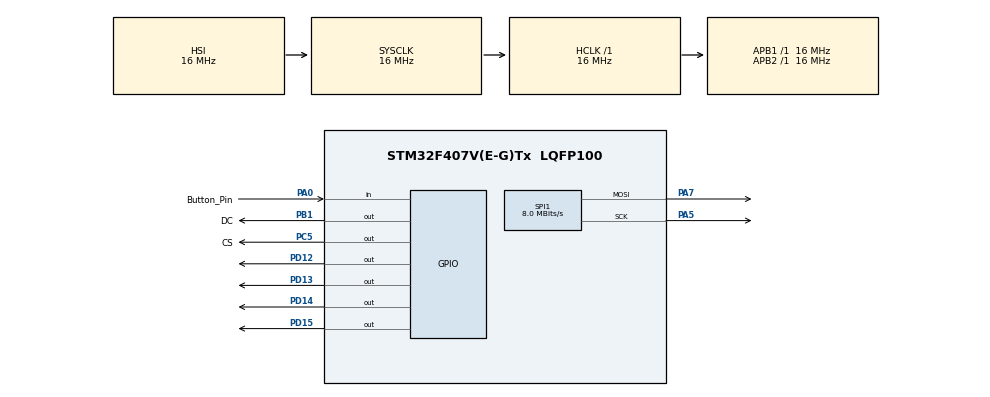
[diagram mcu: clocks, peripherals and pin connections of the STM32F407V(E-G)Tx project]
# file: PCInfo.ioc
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Mcu.Family=STM32F4
Mcu.Name=STM32F407V(E-G)Tx
Mcu.Package=LQFP100
NVIC.PriorityGroup=NVIC_PRIORITYGROUP_4
PA0-WKUP.GPIO_Label=Button_Pin
PA0-WKUP.Signal=GPIO_Input
PA13.Mode=Serial_Wire
PA13.Signal=SYS_JTMS-SWDIO
PA14.Mode=Serial_Wire
PA14.Signal=SYS_JTCK-SWCLK
PA5.Mode=TX_Only_Simplex_Unidirect_Master
PA5.Signal=SPI1_SCK
PA7.Mode=TX_Only_Simplex_Unidirect_Master
PA7.Signal=SPI1_MOSI
PB1.GPIO_Label=DC
PB1.Signal=GPIO_Output
PC5.GPIO_Label=CS
PC5.Signal=GPIO_Output
PD12.Signal=GPIO_Output
PD13.Signal=GPIO_Output
PD14.Signal=GPIO_Output
PD15.Signal=GPIO_Output
ProjectManager.HeapSize=0x200
ProjectManager.StackSize=0x400
ProjectManager.TargetToolchain=SW4STM32
RCC.AHBFreq_Value=16000000
RCC.APB1Freq_Value=16000000
RCC.APB2Freq_Value=16000000
RCC.ClockTypeHCLK=RCC_CLOCKTYPE_HCLK
RCC.ClockTypePCLK1=RCC_CLOCKTYPE_PCLK1
RCC.ClockTypePCLK2=RCC_CLOCKTYPE_PCLK2
RCC.ClockTypeSysClk=RCC_CLOCKTYPE_SYSCLK
RCC.CortexFreq_Value=16000000
RCC.EnableExtClockForI2S=false
RCC.EnableHSE=false
RCC.EnableHSERTCDevisor=false
RCC.EnableLSE=false
RCC.EnableLSERTC=false
RCC.ExtClockEnable=false
RCC.HSEState=RCC_HSE_OFF
RCC.HSE_VALUE=25000000
RCC.HSIState=RCC_HSI_ON
RCC.HSI_VALUE=16000000
RCC.I2SEnable=false
RCC.IWDGEnable=false
RCC.LSE_VALUE=32768
RCC.LSIState=RCC_LSI_OFF
RCC.MCO1OutPutEnable=false
RCC.MCO2OutPutEnable=false
RCC.OscillatorTypeHSI=RCC_OSCILLATORTYPE_HSI
RCC.PLLSource=RCC_PLLSOURCE_HSI
RCC.PLLSourceVirtual=RCC_PLLSOURCE_HSI
RCC.PLLState=RCC_PLL_OFF
RCC.RNGEnable=false
RCC.RTCEnable=false
RCC.SDIOEnable=false
RCC.SYSCLKFreq_VALUE=16000000
RCC.USBFSEnable=false
RCC.USBHSEnable=false
RCC.VCOOutputFreq_Value=192000000
SPI1.BaudRatePrescaler=SPI_BAUDRATEPRESCALER_2
SPI1.CRCPolynomial=10
SPI1.CalculateBaudRate=8.0 MBits/s
SPI1.Direction=SPI_DIRECTION_2LINES
SPI1.Mode=SPI_MODE_MASTER
SPI1.VirtualType=VM_MASTER
board=PCInfo

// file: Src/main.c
/**
  ******************************************************************************
  * File Name          : main.c
  * Description        : Main program body
  ******************************************************************************
  *
  * COPYRIGHT(c) 2017 STMicroelectronics
  *
  * Redistribution and use in source and binary forms, with or without modification,
  * are permitted provided that the following conditions are met:
  *   1. Redistributions of source code must retain the above copyright notice,
  *      this list of conditions and the following disclaimer.
  *   2. Redistributions in binary form must reproduce the above copyright notice,
  *      this list of conditions and the following disclaimer in the documentation
  *      and/or other materials provided with the distribution.
  *   3. Neither the name of STMicroelectronics nor the names of its contributors
  *      may be used to endorse or promote products derived from this software
  *      without specific prior written permission.
  *
  * THIS SOFTWARE IS PROVIDED BY THE COPYRIGHT HOLDERS AND CONTRIBUTORS "AS IS"
  * AND ANY EXPRESS OR IMPLIED WARRANTIES, INCLUDING, BUT NOT LIMITED TO, THE
  * IMPLIED WARRANTIES OF MERCHANTABILITY AND FITNESS FOR A PARTICULAR PURPOSE ARE
  * DISCLAIMED. IN NO EVENT SHALL THE COPYRIGHT HOLDER OR CONTRIBUTORS BE LIABLE
  * FOR ANY DIRECT, INDIRECT, INCIDENTAL, SPECIAL, EXEMPLARY, OR CONSEQUENTIAL
  * DAMAGES (INCLUDING, BUT NOT LIMITED TO, PROCUREMENT OF SUBSTITUTE GOODS OR
  * SERVICES; LOSS OF USE, DATA, OR PROFITS; OR BUSINESS INTERRUPTION) HOWEVER
  * CAUSED AND ON ANY THEORY OF LIABILITY, WHETHER IN CONTRACT, STRICT LIABILITY,
  * OR TORT (INCLUDING NEGLIGENCE OR OTHERWISE) ARISING IN ANY WAY OUT OF THE USE
  * OF THIS SOFTWARE, EVEN IF ADVISED OF THE POSSIBILITY OF SUCH DAMAGE.
  *
  ******************************************************************************
  */
#include "main.h"
#include "stm32f4xx_hal.h"

/* USER CODE BEGIN Includes */

#include "ssd1306.h"
/* USER CODE END Includes */

SPI_HandleTypeDef hspi1;

/* USER CODE BEGIN PV */
/* Private variables ---------------------------------------------------------*/

/* USER CODE END PV */

void SystemClock_Config(void);
void Error_Handler(void);
static void MX_GPIO_Init(void);
static void MX_SPI1_Init(void);

/* USER CODE BEGIN PFP */
/* Private function prototypes -----------------------------------------------*/

/* USER CODE END PFP */

int main(void)
{

  /* MCU Configuration----------------------------------------------------------*/

  /* Reset of all peripherals, Initializes the Flash interface and the Systick. */
  HAL_Init();

  /* Configure the system clock */
  SystemClock_Config();

  /* Initialize all configured peripherals */
  MX_GPIO_Init();
  MX_SPI1_Init();

  /* USER CODE BEGIN 2 */
  ssd1306Init(SSD1306_CHARGEPUMP);
  ssd1306ClearScreen( LAYER0 | LAYER1 );
  ssd1306Refresh();
  HAL_Delay(100);

  ssd1306DrawString(10, 32, "Hellooo!", 3, WHITE, LAYER1);
  ssd1306Refresh();

  /* USER CODE END 2 */

  /* Infinite loop */
  while (1)
  {

  /* USER CODE BEGIN 3 */
	  if(HAL_GPIO_ReadPin(Button_Pin_GPIO_Port, Button_Pin_Pin) == GPIO_PIN_SET){
		  HAL_GPIO_WritePin(GPIOD, GPIO_PIN_15|GPIO_PIN_14|GPIO_PIN_13|GPIO_PIN_12, GPIO_PIN_SET);
	  }else{
		  HAL_GPIO_WritePin(GPIOD, GPIO_PIN_15|GPIO_PIN_14|GPIO_PIN_13|GPIO_PIN_12, GPIO_PIN_RESET);
	  }
	  ssd1306DrawString(10, 32, "Hellooo!", 3, WHITE, LAYER1);
	  ssd1306Refresh();
  }
  /* USER CODE END 3 */

}

/** System Clock Configuration
*/
void SystemClock_Config(void)
{

  RCC_OscInitTypeDef RCC_OscInitStruct;
  RCC_ClkInitTypeDef RCC_ClkInitStruct;

    /**Configure the main internal regulator output voltage
    */
  __HAL_RCC_PWR_CLK_ENABLE();

  __HAL_PWR_VOLTAGESCALING_CONFIG(PWR_REGULATOR_VOLTAGE_SCALE1);

    /**Initializes the CPU, AHB and APB busses clocks
    */
  RCC_OscInitStruct.OscillatorType = RCC_OSCILLATORTYPE_HSI;
  RCC_OscInitStruct.HSIState = RCC_HSI_ON;
  RCC_OscInitStruct.HSICalibrationValue = 16;
  RCC_OscInitStruct.PLL.PLLState = RCC_PLL_NONE;
  if (HAL_RCC_OscConfig(&RCC_OscInitStruct) != HAL_OK)
  {
    Error_Handler();
  }

    /**Initializes the CPU, AHB and APB busses clocks
    */
  RCC_ClkInitStruct.ClockType = RCC_CLOCKTYPE_HCLK|RCC_CLOCKTYPE_SYSCLK
                              |RCC_CLOCKTYPE_PCLK1|RCC_CLOCKTYPE_PCLK2;
  RCC_ClkInitStruct.SYSCLKSource = RCC_SYSCLKSOURCE_HSI;
  RCC_ClkInitStruct.AHBCLKDivider = RCC_SYSCLK_DIV1;
  RCC_ClkInitStruct.APB1CLKDivider = RCC_HCLK_DIV1;
  RCC_ClkInitStruct.APB2CLKDivider = RCC_HCLK_DIV1;

  if (HAL_RCC_ClockConfig(&RCC_ClkInitStruct, FLASH_LATENCY_0) != HAL_OK)
  {
    Error_Handler();
  }

    /**Configure the Systick interrupt time
    */
  HAL_SYSTICK_Config(HAL_RCC_GetHCLKFreq()/1000);

    /**Configure the Systick
    */
  HAL_SYSTICK_CLKSourceConfig(SYSTICK_CLKSOURCE_HCLK);

  /* SysTick_IRQn interrupt configuration */
  HAL_NVIC_SetPriority(SysTick_IRQn, 0, 0);
}

/* SPI1 init function */
static void MX_SPI1_Init(void)
{

  hspi1.Instance = SPI1;
  hspi1.Init.Mode = SPI_MODE_MASTER;
  hspi1.Init.Direction = SPI_DIRECTION_2LINES;
  hspi1.Init.DataSize = SPI_DATASIZE_8BIT;
  hspi1.Init.CLKPolarity = SPI_POLARITY_LOW;
  hspi1.Init.CLKPhase = SPI_PHASE_1EDGE;
  hspi1.Init.NSS = SPI_NSS_SOFT;
  hspi1.Init.BaudRatePrescaler = SPI_BAUDRATEPRESCALER_16;
  hspi1.Init.FirstBit = SPI_FIRSTBIT_MSB;
  hspi1.Init.TIMode = SPI_TIMODE_DISABLE;
  hspi1.Init.CRCCalculation = SPI_CRCCALCULATION_DISABLE;
  hspi1.Init.CRCPolynomial = 10;
  if (HAL_SPI_Init(&hspi1) != HAL_OK)
  {
    Error_Handler();
  }

}

/** Configure pins as
        * Analog
        * Input
        * Output
        * EVENT_OUT
        * EXTI
*/
static void MX_GPIO_Init(void)
{

  GPIO_InitTypeDef GPIO_InitStruct;

  /* GPIO Ports Clock Enable */
  __HAL_RCC_GPIOA_CLK_ENABLE();
  __HAL_RCC_GPIOC_CLK_ENABLE();
  __HAL_RCC_GPIOB_CLK_ENABLE();
  __HAL_RCC_GPIOD_CLK_ENABLE();

  /*Configure GPIO pin Output Level */
  HAL_GPIO_WritePin(CS_GPIO_Port, CS_Pin, GPIO_PIN_RESET);

  /*Configure GPIO pin Output Level */
  HAL_GPIO_WritePin(DC_GPIO_Port, DC_Pin, GPIO_PIN_RESET);

  /*Configure GPIO pin Output Level */
  HAL_GPIO_WritePin(GPIOD, GPIO_PIN_12|GPIO_PIN_13|GPIO_PIN_14|GPIO_PIN_15, GPIO_PIN_RESET);

  /*Configure GPIO pin : Button_Pin_Pin */
  GPIO_InitStruct.Pin = Button_Pin_Pin;
  GPIO_InitStruct.Mode = GPIO_MODE_INPUT;
  GPIO_InitStruct.Pull = GPIO_NOPULL;
  HAL_GPIO_Init(Button_Pin_GPIO_Port, &GPIO_InitStruct);

  /*Configure GPIO pin : CS_Pin */
  GPIO_InitStruct.Pin = CS_Pin;
  GPIO_InitStruct.Mode = GPIO_MODE_OUTPUT_PP;
  GPIO_InitStruct.Pull = GPIO_NOPULL;
  GPIO_InitStruct.Speed = GPIO_SPEED_FREQ_HIGH;
  HAL_GPIO_Init(CS_GPIO_Port, &GPIO_InitStruct);

  /*Configure GPIO pin : DC_Pin */
  GPIO_InitStruct.Pin = DC_Pin;
  GPIO_InitStruct.Mode = GPIO_MODE_OUTPUT_PP;
  GPIO_InitStruct.Pull = GPIO_NOPULL;
  GPIO_InitStruct.Speed = GPIO_SPEED_FREQ_HIGH;
  HAL_GPIO_Init(DC_GPIO_Port, &GPIO_InitStruct);

  /*Configure GPIO pins : PD12 PD13 PD14 PD15 */
  GPIO_InitStruct.Pin = GPIO_PIN_12|GPIO_PIN_13|GPIO_PIN_14|GPIO_PIN_15;
  GPIO_InitStruct.Mode = GPIO_MODE_OUTPUT_PP;
  GPIO_InitStruct.Pull = GPIO_NOPULL;
  GPIO_InitStruct.Speed = GPIO_SPEED_FREQ_LOW;
  HAL_GPIO_Init(GPIOD, &GPIO_InitStruct);

}

void Error_Handler(void)
{
  while(1)
  {
  }
}

/************************ (C) COPYRIGHT STMicroelectronics *****END OF FILE****/
